# STM32L496xx register map
File version: 1.0
Registers are 32-bit, access not given, reset 0x0 unless marked. A register's access mark holds for its fields unless they carry their own. Offsets are from the block's base; [hi:lo] are bit positions; {n}, {i} and the like mark numbered series; 'fields as' and 'values as' point back to an identical list.

## SAI1
Base 0x40015400
Same registers: SAI2 0x40015800
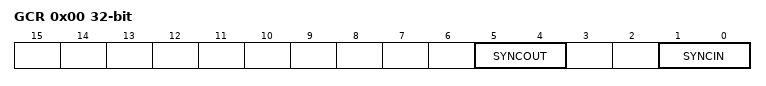
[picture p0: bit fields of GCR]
0x00 GCR
  [5:4] SYNCOUT, [1:0] SYNCIN
0x04 CR1A
0x08 CR2A
0x10 FRCRA
0x1C SLOTRA
0x24 CR1B
0x28 CR2B
0x2C IMRA
0x30 FRCRB
0x3C SLOTRB
0x40 SRA
0x4C IMRB
0x58 CLRFRA
0x60 SRB
0x74 DRA
0x78 CLRFRB
0x94 DRB

## DFSDM1
Base 0x40016000
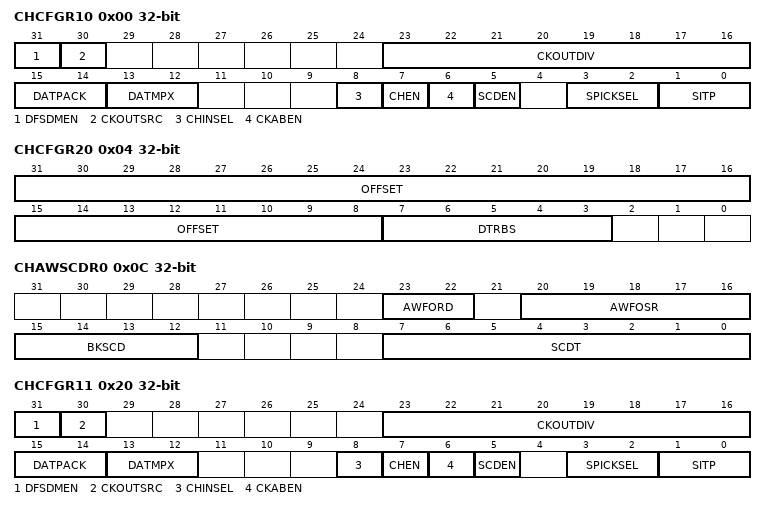
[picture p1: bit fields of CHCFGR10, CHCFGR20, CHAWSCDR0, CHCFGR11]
0x00 CHCFGR10
  [31] DFSDMEN, [30] CKOUTSRC, [23:16] CKOUTDIV, [15:14] DATPACK, [13:12] DATMPX, [8] CHINSEL, [7] CHEN, [6] CKABEN, [5] SCDEN, [3:2] SPICKSEL, [1:0] SITP
0x04 CHCFGR20
  [31:8] OFFSET, [7:3] DTRBS
0x0C CHAWSCDR0
  [23:22] AWFORD, [20:16] AWFOSR, [15:12] BKSCD, [7:0] SCDT
0x18 CHWDATAR0
0x20 CHCFGR11
  fields as CHCFGR10
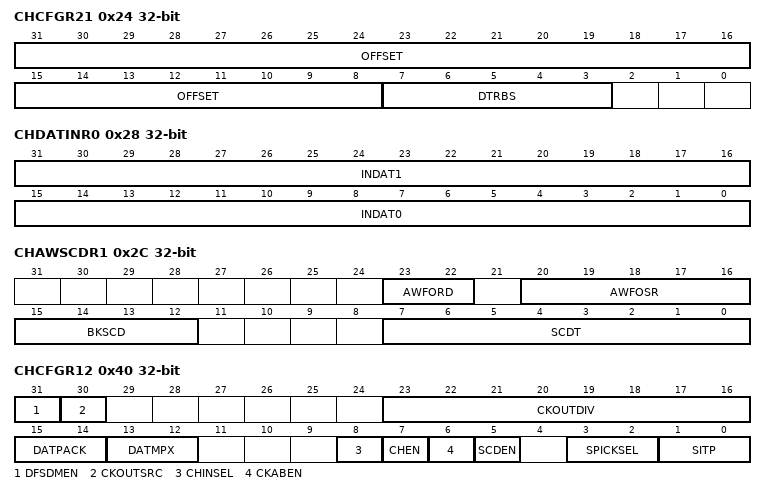
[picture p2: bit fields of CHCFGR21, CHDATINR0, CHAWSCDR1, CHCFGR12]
0x24 CHCFGR21
  [31:8] OFFSET, [7:3] DTRBS
0x28 CHDATINR0
  [31:16] INDAT1, [15:0] INDAT0
0x2C CHAWSCDR1
  [23:22] AWFORD, [20:16] AWFOSR, [15:12] BKSCD, [7:0] SCDT
0x38 CHWDATAR1
0x40 CHCFGR12
  fields as CHCFGR10
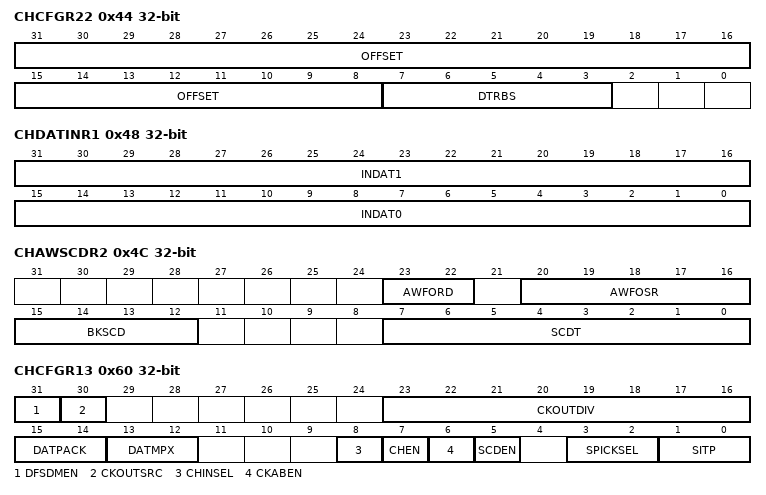
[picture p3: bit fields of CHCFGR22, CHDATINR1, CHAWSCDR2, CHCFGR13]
0x44 CHCFGR22
  [31:8] OFFSET, [7:3] DTRBS
0x48 CHDATINR1
  [31:16] INDAT1, [15:0] INDAT0
0x4C CHAWSCDR2
  [23:22] AWFORD, [20:16] AWFOSR, [15:12] BKSCD, [7:0] SCDT
0x58 CHWDATAR2
0x60 CHCFGR13
  fields as CHCFGR10
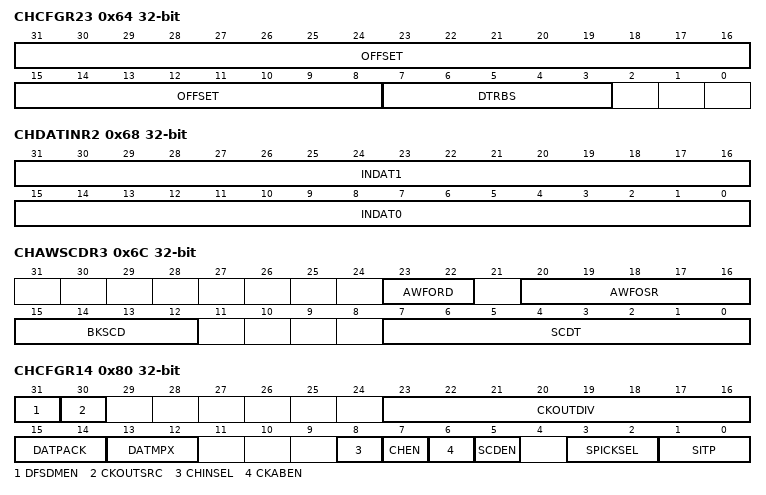
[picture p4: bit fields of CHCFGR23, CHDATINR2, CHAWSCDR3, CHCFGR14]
0x64 CHCFGR23
  [31:8] OFFSET, [7:3] DTRBS
0x68 CHDATINR2
  [31:16] INDAT1, [15:0] INDAT0
0x6C CHAWSCDR3
  [23:22] AWFORD, [20:16] AWFOSR, [15:12] BKSCD, [7:0] SCDT
0x78 CHWDATAR3
0x80 CHCFGR14
  fields as CHCFGR10
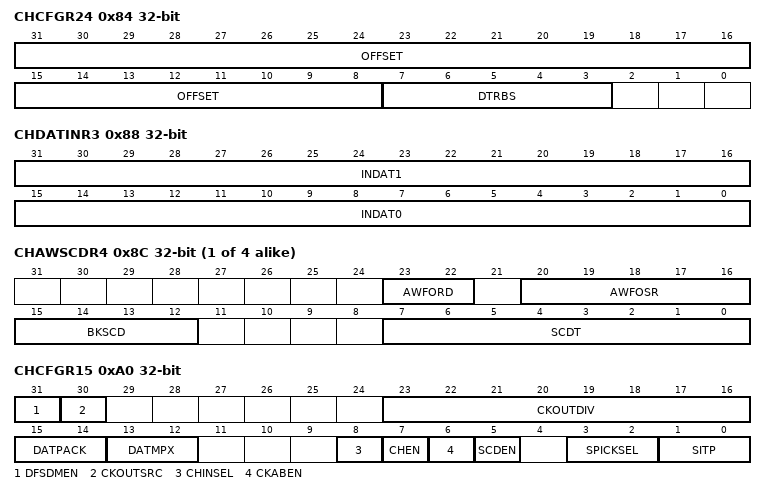
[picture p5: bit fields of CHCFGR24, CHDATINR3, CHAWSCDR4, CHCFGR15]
0x84 CHCFGR24
  [31:8] OFFSET, [7:3] DTRBS
0x88 CHDATINR3
  [31:16] INDAT1, [15:0] INDAT0
{0xC+0x20*i} CHAWSCDR{i} (i=4..7)
  [23:22] AWFORD, [20:16] AWFOSR, [15:12] BKSCD, [7:0] SCDT
{0x18+0x20*i} CHWDATAR{i} (i=4..7)
0xA0 CHCFGR15
  fields as CHCFGR10
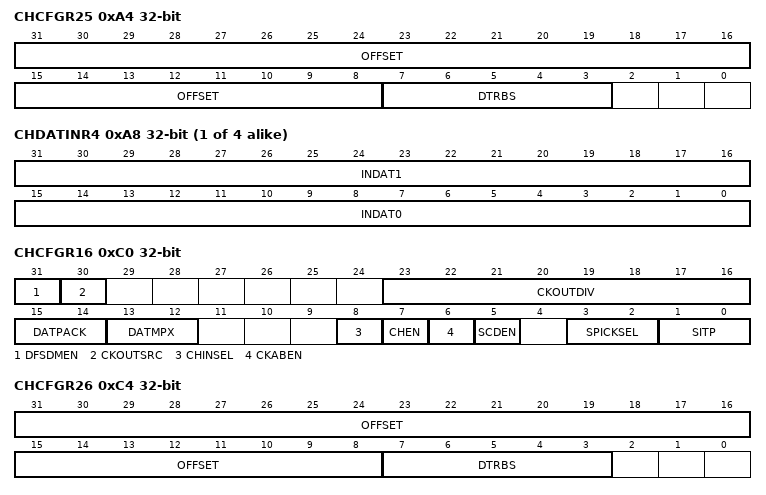
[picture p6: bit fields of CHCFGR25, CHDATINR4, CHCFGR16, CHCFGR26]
0xA4 CHCFGR25
  [31:8] OFFSET, [7:3] DTRBS
{0x28+0x20*i} CHDATINR{i} (i=4..7)
  [31:16] INDAT1, [15:0] INDAT0
0xC0 CHCFGR16
  fields as CHCFGR10
0xC4 CHCFGR26
  [31:8] OFFSET, [7:3] DTRBS
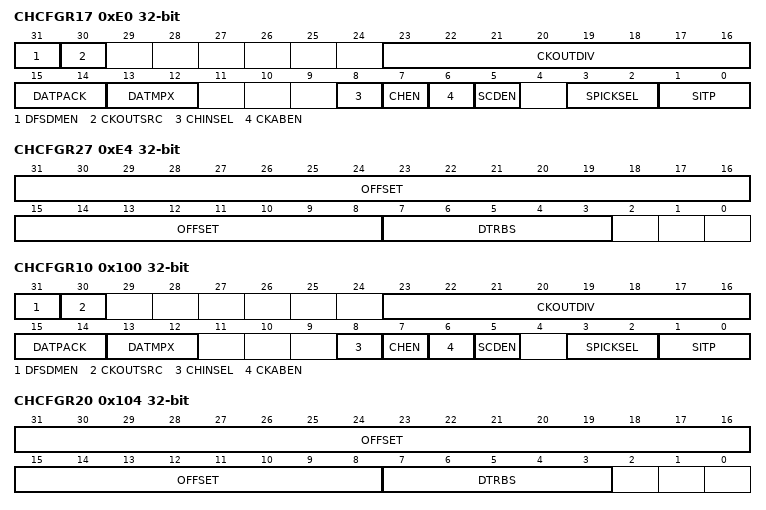
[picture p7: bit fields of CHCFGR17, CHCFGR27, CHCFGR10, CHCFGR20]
0xE0 CHCFGR17
  fields as CHCFGR10
0xE4 CHCFGR27
  [31:8] OFFSET, [7:3] DTRBS
0x100 CHCFGR10
  fields as CHCFGR10
0x104 CHCFGR20
  [31:8] OFFSET, [7:3] DTRBS
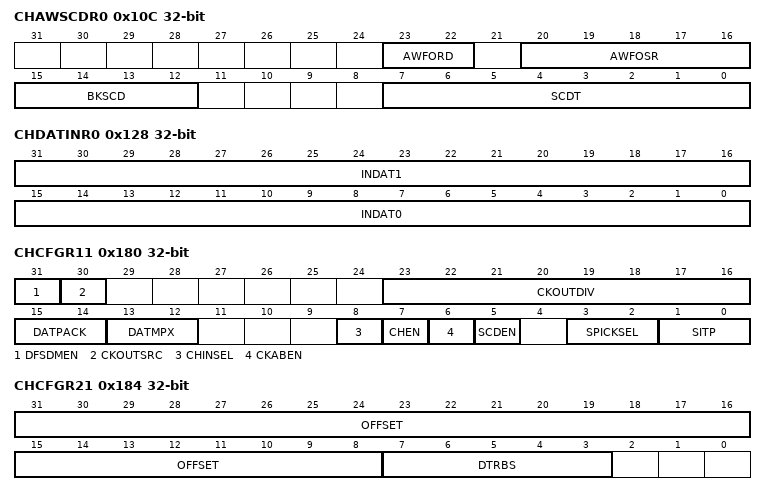
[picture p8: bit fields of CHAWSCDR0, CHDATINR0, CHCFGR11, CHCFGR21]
0x10C CHAWSCDR0
  [23:22] AWFORD, [20:16] AWFOSR, [15:12] BKSCD, [7:0] SCDT
0x118 CHWDATAR0
0x128 CHDATINR0
  [31:16] INDAT1, [15:0] INDAT0
0x180 CHCFGR11
  fields as CHCFGR10
0x184 CHCFGR21
  [31:8] OFFSET, [7:3] DTRBS
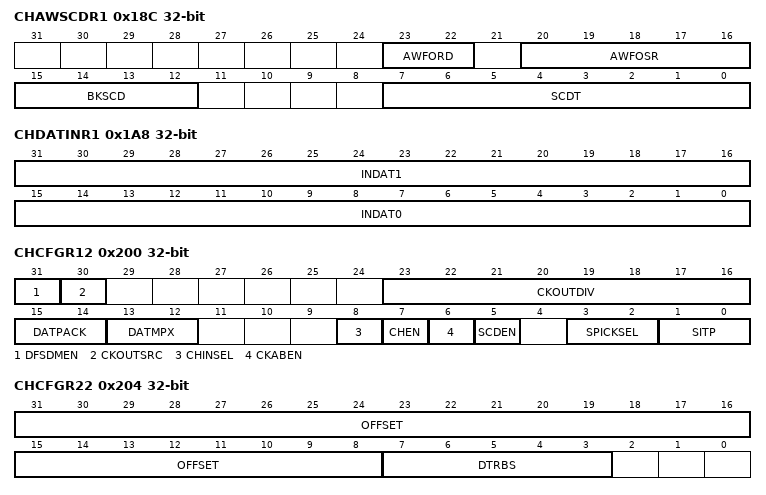
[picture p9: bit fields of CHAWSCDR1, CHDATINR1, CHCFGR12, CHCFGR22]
0x18C CHAWSCDR1
  [23:22] AWFORD, [20:16] AWFOSR, [15:12] BKSCD, [7:0] SCDT
0x198 CHWDATAR1
0x1A8 CHDATINR1
  [31:16] INDAT1, [15:0] INDAT0
0x200 CHCFGR12
  fields as CHCFGR10
0x204 CHCFGR22
  [31:8] OFFSET, [7:3] DTRBS
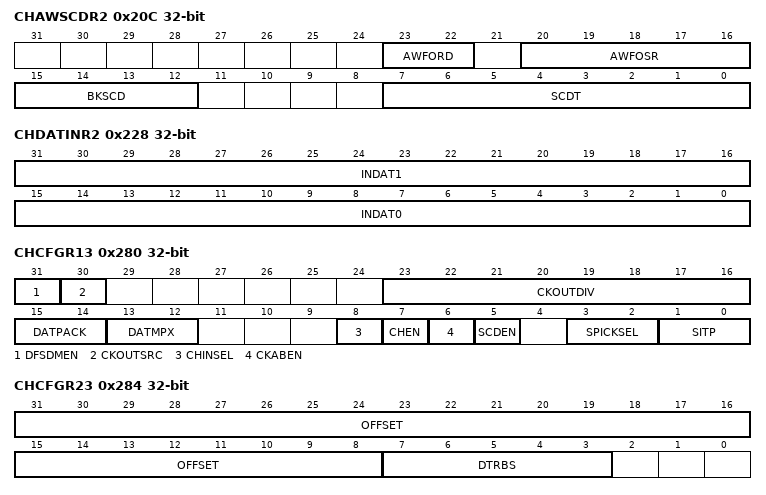
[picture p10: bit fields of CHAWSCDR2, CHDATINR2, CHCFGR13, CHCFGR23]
0x20C CHAWSCDR2
  [23:22] AWFORD, [20:16] AWFOSR, [15:12] BKSCD, [7:0] SCDT
0x218 CHWDATAR2
0x228 CHDATINR2
  [31:16] INDAT1, [15:0] INDAT0
0x280 CHCFGR13
  fields as CHCFGR10
0x284 CHCFGR23
  [31:8] OFFSET, [7:3] DTRBS
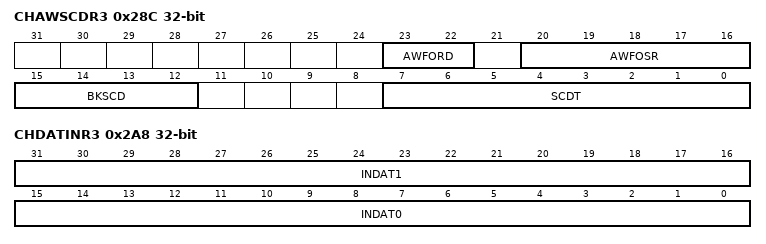
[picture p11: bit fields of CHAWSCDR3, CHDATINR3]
0x28C CHAWSCDR3
  [23:22] AWFORD, [20:16] AWFOSR, [15:12] BKSCD, [7:0] SCDT
0x298 CHWDATAR3
0x2A8 CHDATINR3
  [31:16] INDAT1, [15:0] INDAT0

## DMA1
Base 0x40020000
Same registers: DMA2 0x40020400
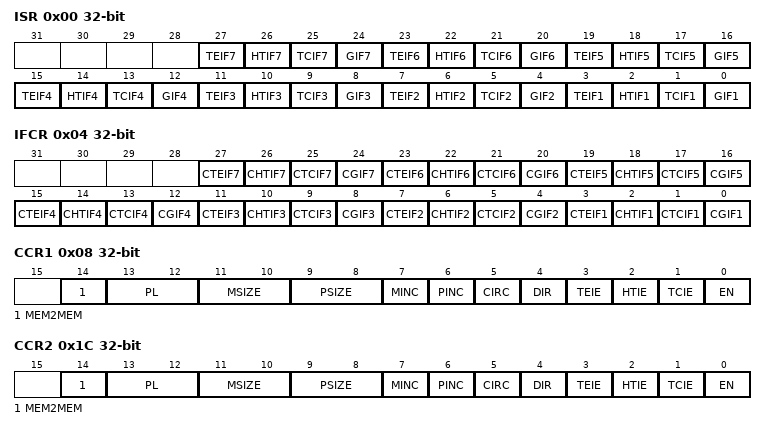
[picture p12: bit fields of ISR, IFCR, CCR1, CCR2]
0x00 ISR
  [4n-1] TEIF{n} (n=1..7), [4n-2] HTIF{n} (n=1..7), [4n-3] TCIF{n} (n=1..7), [4n-4] GIF{n} (n=1..7)
0x04 IFCR
  [4n-1] CTEIF{n} (n=1..7), [4n-2] CHTIF{n} (n=1..7), [4n-3] CTCIF{n} (n=1..7), [4n-4] CGIF{n} (n=1..7)
0x08 CCR1
  [14] MEM2MEM, [13:12] PL, [11:10] MSIZE, [9:8] PSIZE, [7] MINC, [6] PINC, [5] CIRC, [4] DIR, [3] TEIE, [2] HTIE, [1] TCIE, [0] EN
0x0C CNDTR1
  [15:0] NDT
{0x0+0x14*i} CPAR{i} (i=1..7)
  [31:0] PA
0x1C CCR2
  fields as CCR1
{0xC+0x14*i} CMAR{i} (i=1..7)
  [31:0] MA
0x20 CNDTR2
  [15:0] NDT
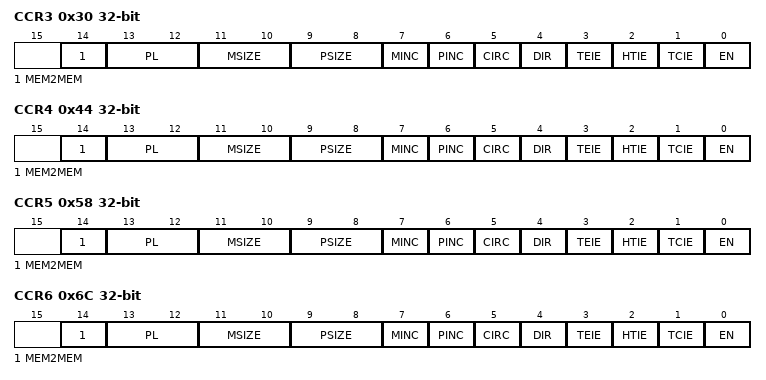
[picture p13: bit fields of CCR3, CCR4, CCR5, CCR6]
0x30 CCR3
  fields as CCR1
0x34 CNDTR3
  [15:0] NDT
0x44 CCR4
  fields as CCR1
0x48 CNDTR4
  [15:0] NDT
0x58 CCR5
  fields as CCR1
0x5C CNDTR5
  [15:0] NDT
0x6C CCR6
  fields as CCR1
0x70 CNDTR6
  [15:0] NDT
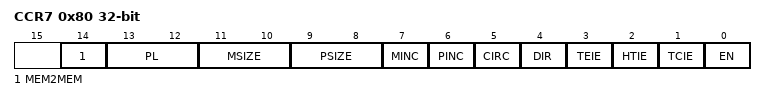
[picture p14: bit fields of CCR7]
0x80 CCR7
  fields as CCR1
0x84 CNDTR7
  [15:0] NDT

## DMA1_CSELR
Base 0x400200A8
Same registers: DMA2_CSELR 0x400204A8
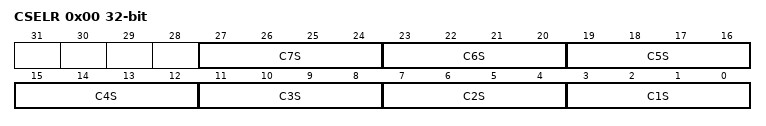
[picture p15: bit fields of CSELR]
0x00 CSELR
  [4n-1:4n-4] C{n}S (n=1..7)

## FLASH
Base 0x40022000
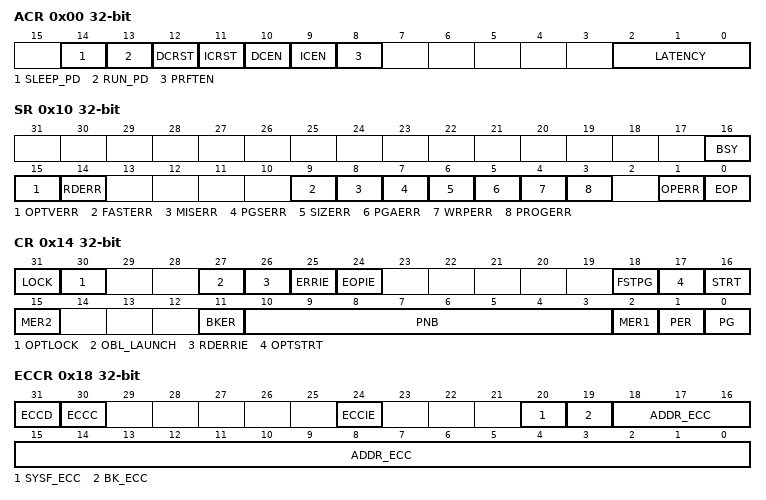
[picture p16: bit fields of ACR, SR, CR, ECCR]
0x00 ACR
  [14] SLEEP_PD, [13] RUN_PD, [12] DCRST, [11] ICRST, [10] DCEN, [9] ICEN, [8] PRFTEN, [2:0] LATENCY
0x04 PDKEYR
0x08 KEYR
0x0C OPTKEYR
0x10 SR
  [16] BSY, [15] OPTVERR, [14] RDERR, [9] FASTERR, [8] MISERR, [7] PGSERR, [6] SIZERR, [5] PGAERR, [4] WRPERR, [3] PROGERR, [1] OPERR, [0] EOP
0x14 CR
  [31] LOCK, [30] OPTLOCK, [27] OBL_LAUNCH, [26] RDERRIE, [25] ERRIE, [24] EOPIE, [18] FSTPG, [17] OPTSTRT, [16] STRT, [15] MER2, [11] BKER, [10:3] PNB, [2] MER1, [1] PER, [0] PG
0x18 ECCR
  [31] ECCD, [30] ECCC, [24] ECCIE, [20] SYSF_ECC, [19] BK_ECC, [18:0] ADDR_ECC
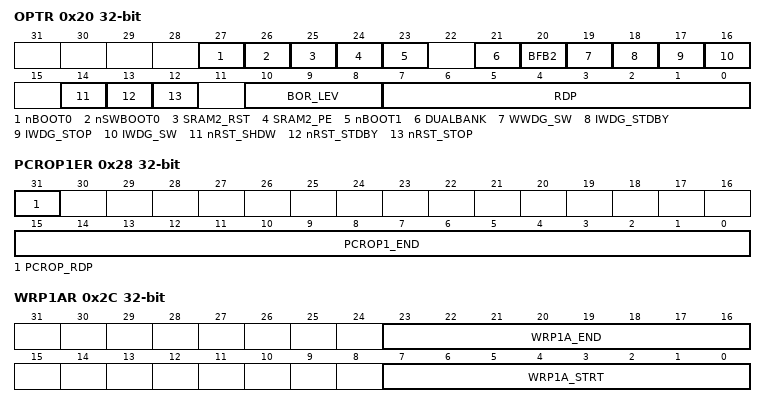
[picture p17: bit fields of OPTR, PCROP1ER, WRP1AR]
0x20 OPTR
  [27] nBOOT0, [26] nSWBOOT0, [25] SRAM2_RST, [24] SRAM2_PE, [23] nBOOT1, [21] DUALBANK, [20] BFB2, [19] WWDG_SW, [18] IWDG_STDBY, [17] IWDG_STOP, [16] IWDG_SW, [14] nRST_SHDW, [13] nRST_STDBY, [12] nRST_STOP, [10:8] BOR_LEV, [7:0] RDP
0x24 PCROP1SR
  [15:0] PCROP1_STRT
0x28 PCROP1ER
  [31] PCROP_RDP, [15:0] PCROP1_END
0x2C WRP1AR
  [23:16] WRP1A_END, [7:0] WRP1A_STRT
0x30 WRP1BR
  [23:16] WRP1B_END, [7:0] WRP1B_STRT
0x44 PCROP2SR
  [15:0] PCROP2_STRT
0x48 PCROP2ER
  [15:0] PCROP2_END
0x4C WRP2AR
  [23:16] WRP2A_END, [7:0] WRP2A_STRT
0x50 WRP2BR
  [23:16] WRP2B_END, [7:0] WRP2B_STRT
